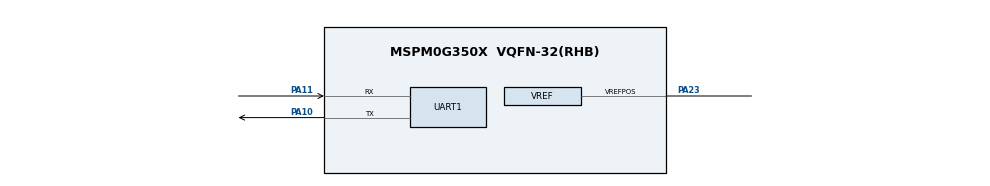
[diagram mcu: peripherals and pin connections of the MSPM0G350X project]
/**
 * @cliArgs --device "MSPM0G350X" --part "Default" --package "VQFN-32(RHB)" --product "mspm0_sdk@2.10.00.04"
 * @versions {"tool":"1.26.2+4477"}
 */

/**
 * Import the modules used in this configuration.
 */
const DAC12  = scripting.addModule("/ti/driverlib/DAC12");
const GPIO   = scripting.addModule("/ti/driverlib/GPIO", {}, false);
const GPIO1  = GPIO.addInstance();
const GPIO2  = GPIO.addInstance();
const GPIO3  = GPIO.addInstance();
const GPIO4  = GPIO.addInstance();
const SYSCTL = scripting.addModule("/ti/driverlib/SYSCTL");
const UART   = scripting.addModule("/ti/driverlib/UART", {}, false);
const UART1  = UART.addInstance();
const VREF   = scripting.addModule("/ti/driverlib/VREF");

/**
 * Write custom configuration values to the imported modules.
 */
const gate8  = system.clockTree["MFPCLKGATE"];
gate8.enable = true;

DAC12.dacOutputPinEn     = true;
DAC12.dacAmplifier       = "ON";
DAC12.dacPosVREF         = "VEREFP";
DAC12.dacNegVREF         = "VEREFN";
DAC12.OutPinConfig.$name = "ti_driverlib_gpio_GPIOPinGeneric1";

const Board           = scripting.addModule("/ti/driverlib/Board", {}, false);
Board.configureUnused = true;

GPIO1.$name                                       = "BRIDGE_LASER";
GPIO1.associatedPins[0].$name                     = "LASER";
GPIO1.associatedPins[0].assignedPort              = "PORTA";
GPIO1.associatedPins[0].assignedPin               = "21";
GPIO1.associatedPins[0].pin.$assignAllowConflicts = "PA21";

GPIO2.$name                          = "BRIDGE_DUMMY";
GPIO2.associatedPins[0].$name        = "DUMMY";
GPIO2.associatedPins[0].assignedPort = "PORTA";
GPIO2.associatedPins[0].assignedPin  = "22";
GPIO2.associatedPins[0].initialValue = "SET";

GPIO3.$name                              = "BUTTON";
GPIO3.associatedPins[0].$name            = "TRIGGER";
GPIO3.associatedPins[0].direction        = "INPUT";
GPIO3.associatedPins[0].internalResistor = "PULL_DOWN";
GPIO3.associatedPins[0].assignedPort     = "PORTA";
GPIO3.associatedPins[0].assignedPin      = "3";

GPIO4.$name                          = "GPIO_LEDS";
GPIO4.associatedPins[0].$name        = "USER_LED_1";
GPIO4.associatedPins[0].assignedPort = "PORTA";
GPIO4.associatedPins[0].initialValue = "SET";
GPIO4.associatedPins[0].assignedPin  = "13";

SYSCTL.MFPCLKEn              = true;
SYSCTL.forceDefaultClkConfig = true;
SYSCTL.clockTreeEn           = true;

UART1.$name                    = "UART_0";
UART1.rxFifoThreshold          = "DL_UART_RX_FIFO_LEVEL_ONE_ENTRY";
UART1.enableDMARX              = false;
UART1.enableDMATX              = false;
UART1.enabledInterrupts        = ["RX"];
UART1.peripheral.$assign       = "UART0";
UART1.peripheral.rxPin.$assign = "PA11";
UART1.peripheral.txPin.$assign = "PA10";
UART1.txPinConfig.$name        = "uart_t";
UART1.rxPinConfig.$name        = "uart";

VREF.basicIntVolt                  = "DL_VREF_BUFCONFIG_OUTPUT_2_5V";
VREF.advClockConfigEnable          = true;
VREF.checkVREFReady                = true;
VREF.profile                       = "INT_2_5_V";
VREF.vrefPosPinConfig.$name        = "ti_driverlib_gpio_GPIOPinGeneric0";
VREF.peripheral.$assign            = "VREF";
VREF.peripheral.vrefPosPin.$assign = "PA23";

const ProjectConfig              = scripting.addModule("/ti/project_config/ProjectConfig", {}, false);
ProjectConfig.migrationCondition = true;

/**
 * Pinmux solution for unlocked pins/peripherals. This ensures that minor changes to the automatic solver in a future
 * version of the tool will not impact the pinmux you originally saw.  These lines can be completely deleted in order to
 * re-solve from scratch.
 */
DAC12.peripheral.$suggestSolution            = "DAC0";
DAC12.peripheral.OutPin.$suggestSolution     = "PA15";
Board.peripheral.$suggestSolution            = "DEBUGSS";
Board.peripheral.swclkPin.$suggestSolution   = "PA20";
Board.peripheral.swdioPin.$suggestSolution   = "PA19";
GPIO2.associatedPins[0].pin.$suggestSolution = "PA22";
GPIO3.associatedPins[0].pin.$suggestSolution = "PA3";
GPIO4.associatedPins[0].pin.$suggestSolution = "PA13";
